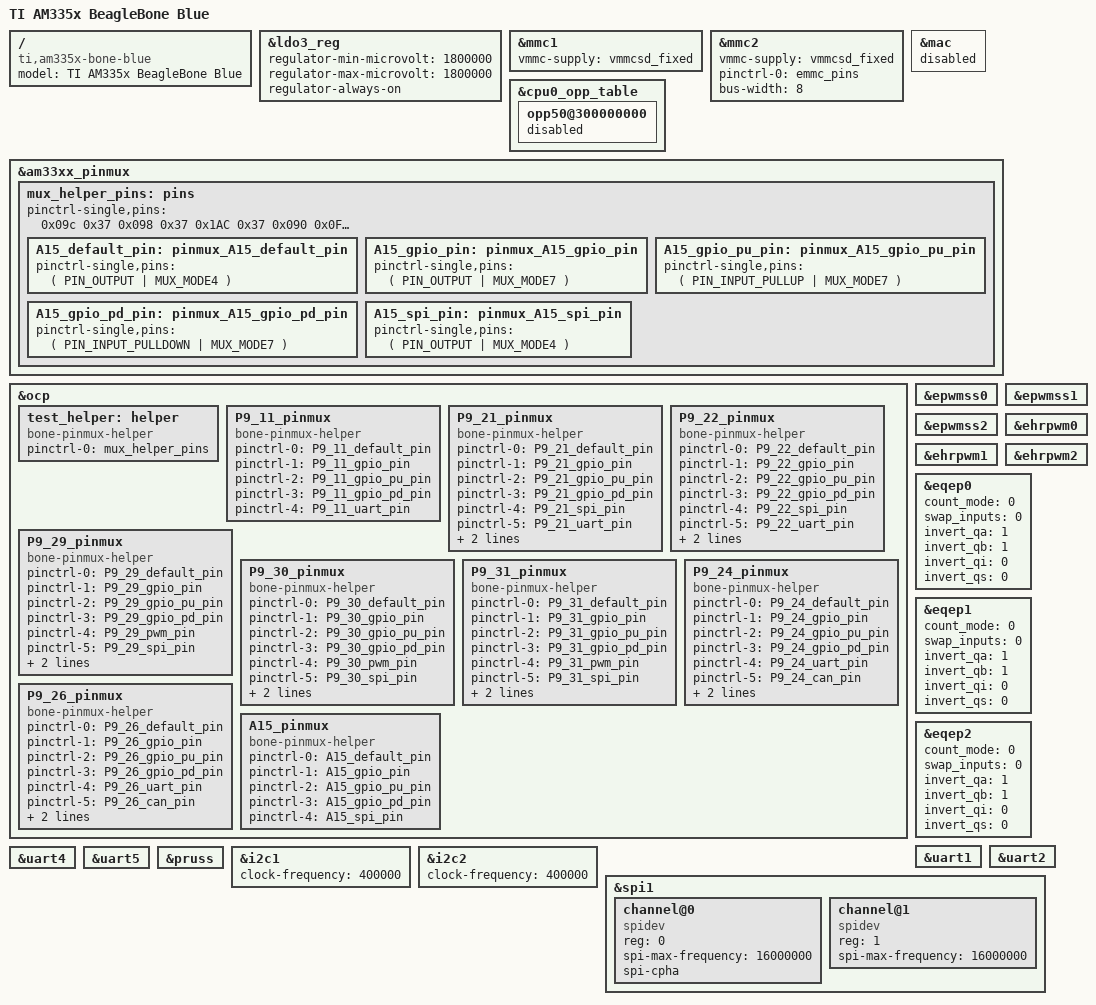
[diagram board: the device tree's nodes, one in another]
/*
 * Copyright (C) 2012 Texas Instruments Incorporated - http://www.ti.com/
 *
 * This program is free software; you can redistribute it and/or modify
 * it under the terms of the GNU General Public License version 2 as
 * published by the Free Software Foundation.
 */
/dts-v1/;

#include "am33xx.dtsi"
#include "am335x-bone-common-no-capemgr.dtsi"
#include "am335x-bone-common-universal-pins.dtsi"
#include "am335x-boneblue-wl1835.dtsi"
#include "am33xx-pruss-rproc.dtsi"

#define BLUE_IO(x, y) AM33XX_IOPAD((x)*4+0x800, (y))


/ {
	model = "TI AM335x BeagleBone Blue";
	compatible = "ti,am335x-bone-blue", "ti,am335x-bone", "ti,am33xx";
};

&ldo3_reg {
	regulator-min-microvolt = <1800000>;
	regulator-max-microvolt = <1800000>;
	regulator-always-on;
};

&mmc1 {
	vmmc-supply = <&vmmcsd_fixed>;
};

&mmc2 {
	vmmc-supply = <&vmmcsd_fixed>;
	pinctrl-names = "default";
	pinctrl-0 = <&emmc_pins>;
	bus-width = <8>;
	status = "okay";
};

&mac {
	status = "disabled";
};

&cpu0_opp_table {
	//osd335x
	opp50@300000000 {
		status = "disabled";
	};
};

/****************************************
* Pin Muxing
****************************************/
&am33xx_pinmux {

	mux_helper_pins: pins {
		pinctrl-single,pins = <

			/* GPIO Inputs */
			0x09c 0x37	/*P8.9  Pause BUTTON, input pullup*/
			0x098 0x37	/*P8.10 MODE BUTTON input pullup*/
			0x1AC 0x37	/*P9.25 MPU-9150 INTERRUPT IN*/

			/* LEDs GPIO Out*/
			0x090 0x0F	/* P8.7 R7 LED_RED */
			0x094 0x0F	/* P8.8 T7 LED_GREEN */
			0x02C 0x0F	/* P8.17 U12 BATT_LED_1 */
			0x0DC 0x0F  /* P8.32 T5  BATT_LED_2 diff from cape! */
			0x07c 0x0F	/* P8.26 V6  BATT_LED_3 */
			0x028 0x0F	/* P8.14 T11 BATT_LED_4 */

			/* Motor Control GPIO Out*/
			0x0a8 0x0F	/*P8.43 MDIR_3B*/
			0x0ac 0x0F	/*P8.44 MDIR_3A*/
			0x0a0 0x0F	/*P8.45 MDIR_4A*/
			0x0a4 0x0F	/*P8.46 MDIR_4B*/
			0x074 0x0F	/*P9.13 MDIR_1B*/
			0x040 0x0F	/*P9.15 MDIR_2A*/
			0x1b4 0x0F	/*P9.41 MOT_STBY*/
			0x088 0x0F	/*T13 MDIR_1A diff from cape! */
			0x0D8 0x0F	/*P8.31  MDIR_2B diff from cape! */

			/* Servo Power Ctrl GPIO Out */
			0x0C8 0x0F	/*P8.36, SERVO_PWR*/

			/* HRPWM 1 */
			0x048  0x6 /* P9_14 | MODE 6 */
			0x04c  0x6 /* P9_16 | MODE 6 */
			 
			/* HRPWM 2 */
			0x020  0x4 /* P8_19 | MODE 4 */
			0x024  0x4 /* P8_13 | MODE 4 */
			
			/* EQEP */
			0x1A0 0x31  /* P9_42,EQEP0A, MODE1 */       
			0x1A4 0x31  /* P9_27,EQEP0B, MODE1 */  
			0x0D4 0x32  /* P8_33,EQEP1B, MODE2 */
			0x0D0 0x32  /* P8_35,EQEP1A, MODE2 */
			0x030 0x34  /* P8_12,EQEP2A, MODE4 */
			0x034 0x34  /* P8_11,EQEP2B, MODE4 */
			
			/* PRU encoder input */
			0x03c 0x36	/* P8_15,PRU0_r31_15,MODE6 */ 
			0x038 0x36	/* P8_16,PRU0_r31_16,MODE6 */
			
			/* PRU Servo output */
			0x0e0 0x05	/*pru1_pru_r30_8, MODE5*/
			0x0e8 0x05	/*pru1_pru_r30_10, MODE5 */
			0x0e4 0x05	/*pr1_pru1_pru_r30_9, MODE5 */
			0x0ec 0x05	/*pru1_pru_r30_11, MODE5 */
			0x0b8 0x05	/*pru1_pru_r30_6, MODE5 */
			0x0bc 0x05	/*pru1_pru_r30_7, MODE5 */
			0x0b0 0x05	/*pru1_pru_r30_4, MODE5 */
			0x0b4 0x05	/*pru1_pru_r30_5, MODE5 */
			
			/* I2C1 */
			0x15C 0x32	/* P9.17,i2c1_scl,INPUT_PULLUP,MODE2 */
			0x158 0x32	/* P9.18,i2c1_sda,INPUT_PULLUP,MODE2 */

			/* I2C2 */
			0x17c  0x73 /* P9.19, i2c2_sda, mode 3 */
			0x178  0x73 /* P9.20, i2c2_sda, mode 3 */

			/* UART5 */
			0x0C4 0x34	/* P8.38,uart5_rxd,MODE4 */
			0x0C0 0x14	/* P8.37,uart5_txd,MODE4 */

			/* WILINK 8 */
			0x08c 0x0F	/*P8.18 V12 A2DP FSYNC */
			0x078 0x0F	/*P9.12 A2DP_CLOCK*/
		>;

		/* A15 SPI1_CS1    */
		A15_default_pin: pinmux_A15_default_pin {
			pinctrl-single,pins = <( PIN_OUTPUT | MUX_MODE4 )>; };
		A15_gpio_pin: pinmux_A15_gpio_pin {
			pinctrl-single,pins = <( PIN_OUTPUT | MUX_MODE7 )>; };
		A15_gpio_pu_pin: pinmux_A15_gpio_pu_pin {
			pinctrl-single,pins = <( PIN_INPUT_PULLUP | MUX_MODE7 )>; };
		A15_gpio_pd_pin: pinmux_A15_gpio_pd_pin {
			pinctrl-single,pins = <( PIN_INPUT_PULLDOWN | MUX_MODE7 )>; };
		A15_spi_pin: pinmux_A15_spi_pin {
			pinctrl-single,pins = <( PIN_OUTPUT | MUX_MODE4 )>; };

	};
	
};

&ocp {
	/****************************************
	 * activates the pinmux helper list of pin modes
	 ****************************************/
	test_helper: helper {
		compatible = "bone-pinmux-helper";
		pinctrl-names = "default";
		pinctrl-0 = <&mux_helper_pins>;

		status = "okay";
	};

	/* DSM2 Pins */
	P9_11_pinmux {
		compatible = "bone-pinmux-helper";
		status = "okay";
		pinctrl-names = "default", "gpio", "gpio_pu", "gpio_pd", "uart";
		pinctrl-0 = <&P9_11_default_pin>;
		pinctrl-1 = <&P9_11_gpio_pin>;
		pinctrl-2 = <&P9_11_gpio_pu_pin>;
		pinctrl-3 = <&P9_11_gpio_pd_pin>;
		pinctrl-4 = <&P9_11_uart_pin>;
	};

	/* GPS UART header pins */
	P9_21_pinmux {
        compatible = "bone-pinmux-helper";
        status = "okay";
        pinctrl-names = "default", "gpio", "gpio_pu", "gpio_pd", "spi", "uart", "i2c", "pwm";
        pinctrl-0 = <&P9_21_default_pin>;
        pinctrl-1 = <&P9_21_gpio_pin>;
        pinctrl-2 = <&P9_21_gpio_pu_pin>;
        pinctrl-3 = <&P9_21_gpio_pd_pin>;
        pinctrl-4 = <&P9_21_spi_pin>;
        pinctrl-5 = <&P9_21_uart_pin>;
        pinctrl-6 = <&P9_21_i2c_pin>;
        pinctrl-7 = <&P9_21_pwm_pin>;
    };

    P9_22_pinmux {
        compatible = "bone-pinmux-helper";
        status = "okay";
        pinctrl-names = "default", "gpio", "gpio_pu", "gpio_pd", "spi", "uart", "i2c", "pwm";
        pinctrl-0 = <&P9_22_default_pin>;
        pinctrl-1 = <&P9_22_gpio_pin>;
        pinctrl-2 = <&P9_22_gpio_pu_pin>;
        pinctrl-3 = <&P9_22_gpio_pd_pin>;
        pinctrl-4 = <&P9_22_spi_pin>;
        pinctrl-5 = <&P9_22_uart_pin>;
        pinctrl-6 = <&P9_22_i2c_pin>;
        pinctrl-7 = <&P9_22_pwm_pin>;
    };

    /* SPI Header Pins */
    /* MISO */
    P9_29_pinmux {
        compatible = "bone-pinmux-helper";
        status = "okay";
        pinctrl-names = "default", "gpio", "gpio_pu", "gpio_pd", "pwm", "spi", "pruout", "pruin";
        pinctrl-0 = <&P9_29_default_pin>;
        pinctrl-1 = <&P9_29_gpio_pin>;
        pinctrl-2 = <&P9_29_gpio_pu_pin>;
        pinctrl-3 = <&P9_29_gpio_pd_pin>;
        pinctrl-4 = <&P9_29_pwm_pin>;
        pinctrl-5 = <&P9_29_spi_pin>;
        pinctrl-6 = <&P9_29_pruout_pin>;
        pinctrl-7 = <&P9_29_pruin_pin>;
    };

    /* MOSI */
    P9_30_pinmux {
        compatible = "bone-pinmux-helper";
        status = "okay";
        pinctrl-names = "default", "gpio", "gpio_pu", "gpio_pd", "pwm", "spi", "pruout", "pruin";
        pinctrl-0 = <&P9_30_default_pin>;
        pinctrl-1 = <&P9_30_gpio_pin>;
        pinctrl-2 = <&P9_30_gpio_pu_pin>;
        pinctrl-3 = <&P9_30_gpio_pd_pin>;
        pinctrl-4 = <&P9_30_pwm_pin>;
        pinctrl-5 = <&P9_30_spi_pin>;
        pinctrl-6 = <&P9_30_pruout_pin>;
        pinctrl-7 = <&P9_30_pruin_pin>;
    };

    /* SCK */
    P9_31_pinmux {
        compatible = "bone-pinmux-helper";
        status = "okay";
        pinctrl-names = "default", "gpio", "gpio_pu", "gpio_pd", "pwm", "spi", "pruout", "pruin";
        pinctrl-0 = <&P9_31_default_pin>;
        pinctrl-1 = <&P9_31_gpio_pin>;
        pinctrl-2 = <&P9_31_gpio_pu_pin>;
        pinctrl-3 = <&P9_31_gpio_pd_pin>;
        pinctrl-4 = <&P9_31_pwm_pin>;
        pinctrl-5 = <&P9_31_spi_pin>;
        pinctrl-6 = <&P9_31_pruout_pin>;
        pinctrl-7 = <&P9_31_pruin_pin>;
    };

    /* uart 1 / can */
     P9_24_pinmux {
        compatible = "bone-pinmux-helper";
        status = "okay";
        pinctrl-names = "default", "gpio", "gpio_pu", "gpio_pd", "uart", "can", "i2c",  "pruin";
        pinctrl-0 = <&P9_24_default_pin>;
        pinctrl-1 = <&P9_24_gpio_pin>;
        pinctrl-2 = <&P9_24_gpio_pu_pin>;
        pinctrl-3 = <&P9_24_gpio_pd_pin>;
        pinctrl-4 = <&P9_24_uart_pin>;
        pinctrl-5 = <&P9_24_can_pin>;
        pinctrl-6 = <&P9_24_i2c_pin>;
        pinctrl-7 = <&P9_24_pruin_pin>;
    };

    P9_26_pinmux {
        compatible = "bone-pinmux-helper";
        status = "okay";
        pinctrl-names = "default", "gpio", "gpio_pu", "gpio_pd", "uart", "can", "i2c",  "pruin";
        pinctrl-0 = <&P9_26_default_pin>;
        pinctrl-1 = <&P9_26_gpio_pin>;
        pinctrl-2 = <&P9_26_gpio_pu_pin>;
        pinctrl-3 = <&P9_26_gpio_pd_pin>;
        pinctrl-4 = <&P9_26_uart_pin>;
        pinctrl-5 = <&P9_26_can_pin>;
        pinctrl-6 = <&P9_26_i2c_pin>;
        pinctrl-7 = <&P9_26_pruin_pin>;
    };

    // SPI SS2
    A15_pinmux {
        compatible = "bone-pinmux-helper";
        status = "okay";
        pinctrl-names = "default", "gpio", "gpio_pu", "gpio_pd", "spi";
        pinctrl-0 = <&A15_default_pin>;
        pinctrl-1 = <&A15_gpio_pin>;
        pinctrl-2 = <&A15_gpio_pu_pin>;
        pinctrl-3 = <&A15_gpio_pd_pin>;
        pinctrl-4 = <&A15_spi_pin>;
    };
};


/****************************************
		PWMSS
****************************************/
&epwmss0 {
	status = "okay";
};

&epwmss1 {
	status = "okay";
};

&epwmss2 {
	status = "okay";
};

&ehrpwm0 {
	status = "okay";
};

&ehrpwm1 {
	status = "okay";
};

&ehrpwm2 {
	status = "okay";
};


/*******************************************************************************
* EQEP
*******************************************************************************/
&eqep0 {
	count_mode = <0>;  /* 0 - Quadrature mode, normal 90 phase offset cha & chb.  1 - Direction mode.  cha input = clock, chb input = direction */
	swap_inputs = <0>; /* Are channel A and channel B swapped? (0 - no, 1 - yes) */
	invert_qa = <1>;   /* Should we invert the channel A input?  */
	invert_qb = <1>;   /* Should we invert the channel B input? I invert these because my encoder outputs drive transistors that pull down the pins */
	invert_qi = <0>;   /* Should we invert the index input? */
	invert_qs = <0>;   /* Should we invert the strobe input? */
	status = "okay";
};

&eqep1 {
	count_mode = <0>;  /* 0 - Quadrature mode, normal 90 phase offset cha & chb.  1 - Direction mode.  cha input = clock, chb input = direction */
	swap_inputs = <0>; /* Are channel A and channel B swapped? (0 - no, 1 - yes) */
	invert_qa = <1>;   /* Should we invert the channel A input?  */
	invert_qb = <1>;   /* Should we invert the channel B input? I invert these because my encoder outputs drive transistors that pull down the pins */
	invert_qi = <0>;   /* Should we invert the index input? */
	invert_qs = <0>;   /* Should we invert the strobe input? */
	status = "okay";
};

&eqep2 {
	count_mode = <0>;  /* 0 - Quadrature mode, normal 90 phase offset cha & chb.  1 - Direction mode.  cha input = clock, chb input = direction */
	swap_inputs = <0>; /* Are channel A and channel B swapped? (0 - no, 1 - yes) */
	invert_qa = <1>;   /* Should we invert the channel A input?  */
	invert_qb = <1>;   /* Should we invert the channel B input? I invert these because my encoder outputs drive transistors that pull down the pins */
	invert_qi = <0>;   /* Should we invert the index input? */
	invert_qs = <0>;   /* Should we invert the strobe input? */
	status = "okay";
};


/****************************************
	UART

	UART 1, 2, 5 are used on the cape.
	The Beaglebone Blue uses others so all are enabled here.
****************************************/

&uart1 {
	status = "okay";
};

&uart2 {
	status = "okay";
};

&uart4 {
	status = "okay";
};

&uart5 {
	status = "okay";
};


/****************************************
		PRU
****************************************/
&pruss {
	status = "okay";
};


/****************************************
		I2C
****************************************/
&i2c1 {
	status = "okay";
	clock-frequency = <400000>;
	#address-cells = <1>;
	#size-cells = <0>;
};

&i2c2 {	 
	status = "okay";
	clock-frequency = <400000>;
	#address-cells = <1>;
	#size-cells = <0>;
};

/****************************************
		SPI
****************************************/
&spi1 {
	#address-cells = <1>;
	#size-cells = <0>;
	status = "okay";

	channel@0 {
		#address-cells = <1>;
		#size-cells = <0>;

		compatible = "spidev";

		reg = <0>;
		spi-max-frequency = <16000000>;
		spi-cpha;
	};

	channel@1 {
		#address-cells = <1>;
		#size-cells = <0>;

		compatible = "spidev";

		reg = <1>;
		spi-max-frequency = <16000000>;
	};
};

